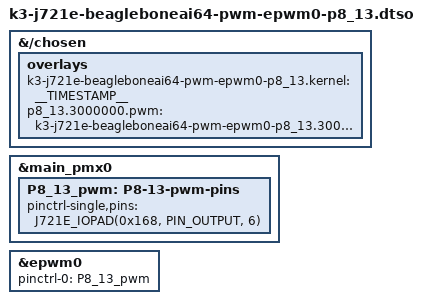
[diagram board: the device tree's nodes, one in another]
// SPDX-License-Identifier: GPL-2.0-only OR MIT
/*
 * DT Overlay for P8_13 epwm0 connections within the expansion header.
 *
 * Copyright (C) 2023 Texas Instruments Incorporated - https://www.ti.com/
 *
 */

/dts-v1/;
/plugin/;

#include <dt-bindings/gpio/gpio.h>
#include "k3-pinctrl.h"

/*
 * Helper to show loaded overlays under: /proc/device-tree/chosen/overlays/
*/
&{/chosen} {
	overlays {
		k3-j721e-beagleboneai64-pwm-epwm0-p8_13.kernel = __TIMESTAMP__;
		p8_13.3000000.pwm = "k3-j721e-beagleboneai64-pwm-epwm0-p8_13.3000000.1.P8_13";
	};
};

&main_pmx0 {
	P8_13_pwm: P8-13-pwm-pins {
		pinctrl-single,pins = <
			J721E_IOPAD(0x168, PIN_OUTPUT, 6) /* (V27) RGMII5_TD1.EHRPWM0_B */
		>;
	};
};

&epwm0 {
	pinctrl-names = "default";
	pinctrl-0 = <&P8_13_pwm>;
	status = "okay";
};
